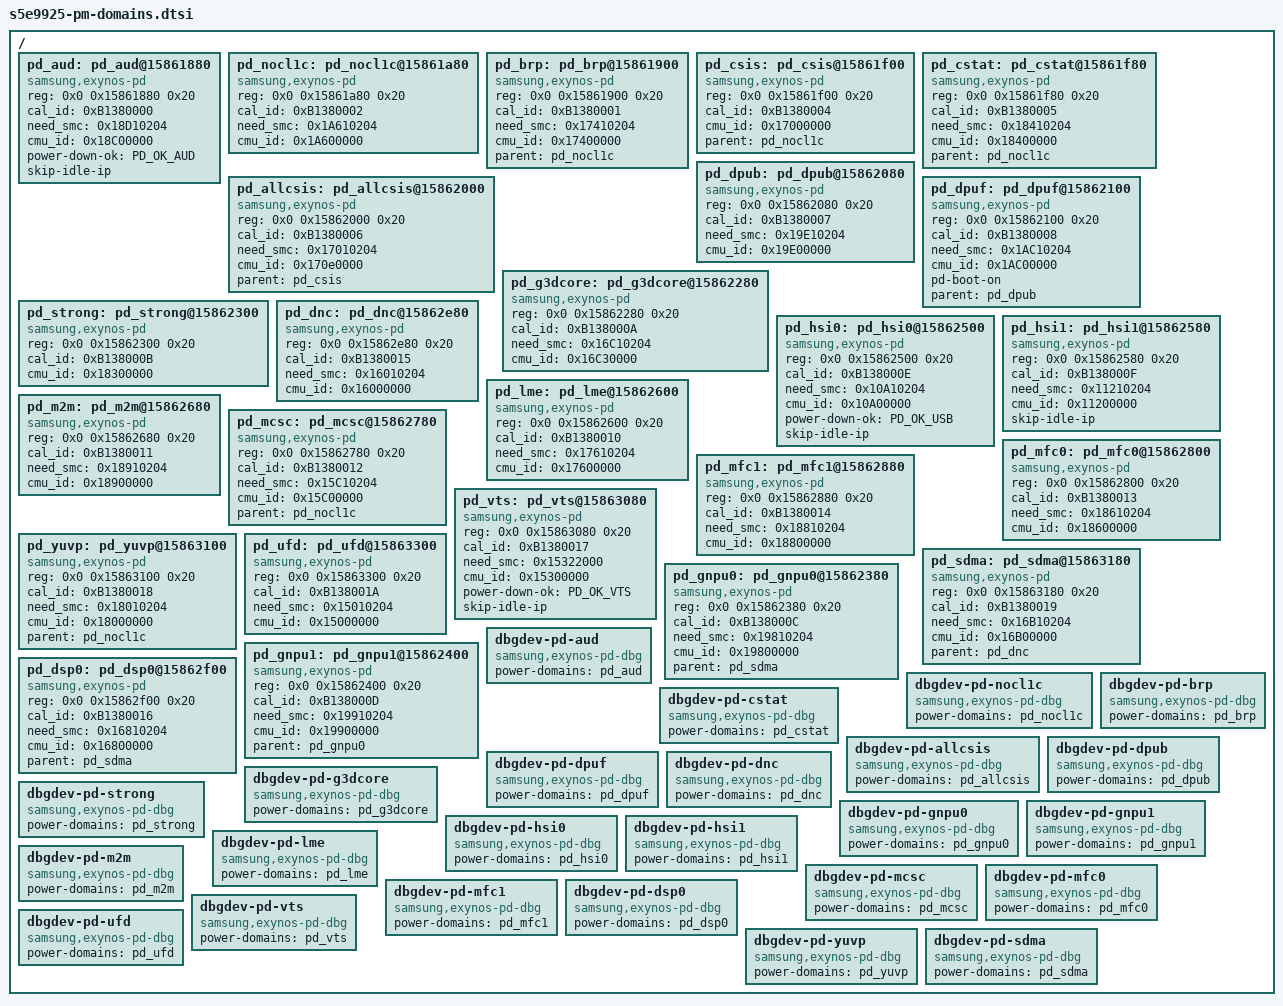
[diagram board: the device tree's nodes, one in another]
/*
 * SAMSUNG S5E9925 SoC PM Domains device tree source
 *
 * Copyright (c) 2019 Samsung Electronics Co., Ltd.
 *		http://www.samsung.com
 *
 * SAMSUNG S5E9925 SoC PM domains device nodes are listed in this file.
 * S5E9925 based board files can include this file and provide
 * values for board specfic bindings.
 *
 * This program is free software; you can redistribute it and/or modify
 * it under the terms of the GNU General Public License version 2 as
 * published by the Free Software Foundation.
 */
#include <dt-bindings/power/exynos-power.h>

/ {
	pd_aud: pd_aud@15861880 {
		compatible = "samsung,exynos-pd";
		reg = <0x0 0x15861880 0x20>;
		cal_id = <0xB1380000>;
		need_smc = <0x18D10204>;
		cmu_id = <0x18C00000>;
		status = "okay";
		power-down-ok = <PD_OK_AUD>;
		#power-domain-cells = <0>;
		skip-idle-ip;
	};
	pd_nocl1c: pd_nocl1c@15861a80 {
		compatible = "samsung,exynos-pd";
		reg = <0x0 0x15861a80 0x20>;
		cal_id = <0xB1380002>;
		need_smc = <0x1A610204>;
		cmu_id = <0x1A600000>;
		status = "okay";
		#power-domain-cells = <0>;
	};
	pd_brp: pd_brp@15861900 {	 
		compatible = "samsung,exynos-pd";
		reg = <0x0 0x15861900 0x20>;
		cal_id = <0xB1380001>;
		need_smc = <0x17410204>;
		cmu_id = <0x17400000>;
		status = "okay";
		parent = <&pd_nocl1c>;
		#power-domain-cells = <0>;
	};
	pd_csis: pd_csis@15861f00 {
		compatible = "samsung,exynos-pd";
		reg = <0x0 0x15861f00 0x20>;
		cal_id = <0xB1380004>;
		cmu_id = <0x17000000>;
		status = "okay";
		parent = <&pd_nocl1c>;
		#power-domain-cells = <0>;
	};
	pd_cstat: pd_cstat@15861f80 {
		compatible = "samsung,exynos-pd";
		reg = <0x0 0x15861f80 0x20>;
		cal_id = <0xB1380005>;
		need_smc = <0x18410204>;
		cmu_id = <0x18400000>;
		status = "okay";
		parent = <&pd_nocl1c>;
		#power-domain-cells = <0>;
	};
	pd_allcsis: pd_allcsis@15862000 {
		compatible = "samsung,exynos-pd";
		reg = <0x0 0x15862000 0x20>;
		cal_id = <0xB1380006>;
		need_smc = <0x17010204>;
		cmu_id = <0x170e0000>;
		status = "okay";
		parent = <&pd_csis>;
		#power-domain-cells = <0>;
	};
	pd_dpub: pd_dpub@15862080 {
		compatible = "samsung,exynos-pd";
		reg = <0x0 0x15862080 0x20>;
		cal_id = <0xB1380007>;
		need_smc = <0x19E10204>;
		cmu_id = <0x19E00000>;
		status = "okay";
		#power-domain-cells = <0>;
	};
	pd_dpuf: pd_dpuf@15862100 {
		compatible = "samsung,exynos-pd";
		reg = <0x0 0x15862100 0x20>;
		cal_id = <0xB1380008>;
		need_smc = <0x1AC10204>;
		cmu_id = <0x1AC00000>;
		status = "okay";
		pd-boot-on;
		parent = <&pd_dpub>;
		#power-domain-cells = <0>;
	};
	pd_g3dcore: pd_g3dcore@15862280 {
		compatible = "samsung,exynos-pd";
		reg = <0x0 0x15862280 0x20>;
		cal_id = <0xB138000A>;
		need_smc = <0x16C10204>;
		cmu_id = <0x16C30000>;
		status = "okay";
		#power-domain-cells = <0>;
	};
	pd_strong: pd_strong@15862300 {
		compatible = "samsung,exynos-pd";
		reg = <0x0 0x15862300 0x20>;
		cal_id = <0xB138000B>;
		cmu_id = <0x18300000>;
		status = "okay";
		#power-domain-cells = <0>;
	};
	pd_dnc: pd_dnc@15862e80 {
		compatible = "samsung,exynos-pd";
		reg = <0x0 0x15862e80 0x20>;
		cal_id = <0xB1380015>;
		need_smc = <0x16010204>;
		cmu_id = <0x16000000>;
		status = "okay";
		#power-domain-cells = <0>;
	};
	pd_hsi0: pd_hsi0@15862500 {
		compatible = "samsung,exynos-pd";
		reg = <0x0 0x15862500 0x20>;
		cal_id = <0xB138000E>;
		need_smc = <0x10A10204>;
		cmu_id = <0x10A00000>;
		status = "okay";
		power-down-ok = <PD_OK_USB>;
		#power-domain-cells = <0>;
		skip-idle-ip;	
	};
	pd_hsi1: pd_hsi1@15862580 {
		compatible = "samsung,exynos-pd";
		reg = <0x0 0x15862580 0x20>;
		cal_id = <0xB138000F>;
		need_smc = <0x11210204>;
		cmu_id = <0x11200000>;
		status = "okay";	
		#power-domain-cells = <0>;
		skip-idle-ip;
	};
	pd_lme: pd_lme@15862600 {
		compatible = "samsung,exynos-pd";
		reg = <0x0 0x15862600 0x20>;
		cal_id = <0xB1380010>;
		need_smc = <0x17610204>;
		cmu_id = <0x17600000>;
		status = "okay";
		#power-domain-cells = <0>;
	};
	pd_m2m: pd_m2m@15862680 {
		compatible = "samsung,exynos-pd";
		reg = <0x0 0x15862680 0x20>;
		cal_id = <0xB1380011>;
		need_smc = <0x18910204>;
		cmu_id = <0x18900000>;
		status = "okay";
		#power-domain-cells = <0>;
	};
	pd_mcsc: pd_mcsc@15862780 {
		compatible = "samsung,exynos-pd";
		reg = <0x0 0x15862780 0x20>;
		cal_id = <0xB1380012>;
		need_smc = <0x15C10204>;
		cmu_id = <0x15C00000>;
		status = "okay";
		parent = <&pd_nocl1c>;
		#power-domain-cells = <0>;
	};
	pd_mfc0: pd_mfc0@15862800 {
		compatible = "samsung,exynos-pd";
		reg = <0x0 0x15862800 0x20>;
		cal_id = <0xB1380013>;
		need_smc = <0x18610204>;
		cmu_id = <0x18600000>;
		status = "okay";
		#power-domain-cells = <0>;
	};
	pd_mfc1: pd_mfc1@15862880 {
		compatible = "samsung,exynos-pd";
		reg = <0x0 0x15862880 0x20>;
		cal_id = <0xB1380014>;
		need_smc = <0x18810204>;
		cmu_id = <0x18800000>;
		status = "okay";
		#power-domain-cells = <0>;
	};
	pd_vts: pd_vts@15863080 {
		compatible = "samsung,exynos-pd";
		reg = <0x0 0x15863080 0x20>;
		cal_id = <0xB1380017>;
		need_smc = <0x15322000>;
		cmu_id = <0x15300000>;
		status = "okay";
		power-down-ok = <PD_OK_VTS>;
		#power-domain-cells = <0>;
		skip-idle-ip;
	};
	pd_yuvp: pd_yuvp@15863100 {
		compatible = "samsung,exynos-pd";
		reg = <0x0 0x15863100 0x20>;
		cal_id = <0xB1380018>;
		need_smc = <0x18010204>;
		cmu_id = <0x18000000>;
		status = "okay";
		parent = <&pd_nocl1c>;
		#power-domain-cells = <0>;
	};
	pd_sdma: pd_sdma@15863180 {
		compatible = "samsung,exynos-pd";
		reg = <0x0 0x15863180 0x20>;
		cal_id = <0xB1380019>;
		need_smc = <0x16B10204>;
		cmu_id = <0x16B00000>;
		status = "okay";
		parent = <&pd_dnc>;
		#power-domain-cells = <0>;
	};
	pd_ufd: pd_ufd@15863300 {
		compatible = "samsung,exynos-pd";
		reg = <0x0 0x15863300 0x20>;
		cal_id = <0xB138001A>;
		need_smc = <0x15010204>;
		cmu_id = <0x15000000>;
		status = "okay";
		#power-domain-cells = <0>;
	};
	pd_gnpu0: pd_gnpu0@15862380 {
		compatible = "samsung,exynos-pd";
		reg = <0x0 0x15862380 0x20>;
		cal_id = <0xB138000C>;
		need_smc = <0x19810204>;
		cmu_id = <0x19800000>;
		status = "okay";
		parent = <&pd_sdma>;
		#power-domain-cells = <0>;
	};
	pd_gnpu1: pd_gnpu1@15862400 {
		compatible = "samsung,exynos-pd";
		reg = <0x0 0x15862400 0x20>;
		cal_id = <0xB138000D>;
		need_smc = <0x19910204>;
		cmu_id = <0x19900000>;
		status = "okay";
		parent = <&pd_gnpu0>;
		#power-domain-cells = <0>;
	};
	pd_dsp0: pd_dsp0@15862f00 {
		compatible = "samsung,exynos-pd";
		reg = <0x0 0x15862f00 0x20>;
		cal_id = <0xB1380016>;
		need_smc = <0x16810204>;
		cmu_id = <0x16800000>;
		status = "okay";
		parent = <&pd_sdma>;
		#power-domain-cells = <0>;
	};
	dbgdev-pd-aud {
		compatible = "samsung,exynos-pd-dbg";
		power-domains = <&pd_aud>;
	};

	dbgdev-pd-nocl1c {
		compatible = "samsung,exynos-pd-dbg";
		power-domains = <&pd_nocl1c>;
	};

	dbgdev-pd-brp {
		compatible = "samsung,exynos-pd-dbg";
		power-domains = <&pd_brp>;
	};

	dbgdev-pd-cstat {
		compatible = "samsung,exynos-pd-dbg";
		power-domains = <&pd_cstat>;
	};

	dbgdev-pd-allcsis {
		compatible = "samsung,exynos-pd-dbg";
		power-domains = <&pd_allcsis>;
	};

	dbgdev-pd-dpub {
		compatible = "samsung,exynos-pd-dbg";
		power-domains = <&pd_dpub>;
	};

	dbgdev-pd-dpuf {
		compatible = "samsung,exynos-pd-dbg";
		power-domains = <&pd_dpuf>;
	};

	dbgdev-pd-g3dcore {
		compatible = "samsung,exynos-pd-dbg";
		power-domains = <&pd_g3dcore>;
	};

	dbgdev-pd-strong {
		compatible = "samsung,exynos-pd-dbg";
		power-domains = <&pd_strong>;
	};

	dbgdev-pd-dnc {
		compatible = "samsung,exynos-pd-dbg";
		power-domains = <&pd_dnc>;
	};

	dbgdev-pd-gnpu0 {
		compatible = "samsung,exynos-pd-dbg";
		power-domains = <&pd_gnpu0>;
	};

	dbgdev-pd-gnpu1 {
		compatible = "samsung,exynos-pd-dbg";
		power-domains = <&pd_gnpu1>;
	};

	dbgdev-pd-hsi0 {
		compatible = "samsung,exynos-pd-dbg";
		power-domains = <&pd_hsi0>;
	};

	dbgdev-pd-hsi1 {
		compatible = "samsung,exynos-pd-dbg";
		power-domains = <&pd_hsi1>;
	};

	dbgdev-pd-lme {
		compatible = "samsung,exynos-pd-dbg";
		power-domains = <&pd_lme>;
	};

	dbgdev-pd-m2m {
		compatible = "samsung,exynos-pd-dbg";
		power-domains = <&pd_m2m>;
	};

	dbgdev-pd-mcsc {
		compatible = "samsung,exynos-pd-dbg";
		power-domains = <&pd_mcsc>;
	};

	dbgdev-pd-mfc0 {
		compatible = "samsung,exynos-pd-dbg";
		power-domains = <&pd_mfc0>;
	};

	dbgdev-pd-mfc1 {
		compatible = "samsung,exynos-pd-dbg";
		power-domains = <&pd_mfc1>;
	};

	dbgdev-pd-dsp0 {
		compatible = "samsung,exynos-pd-dbg";
		power-domains = <&pd_dsp0>;
	};

	dbgdev-pd-vts {
		compatible = "samsung,exynos-pd-dbg";
		power-domains = <&pd_vts>;
	};

	dbgdev-pd-yuvp {
		compatible = "samsung,exynos-pd-dbg";
		power-domains = <&pd_yuvp>;
	};

	dbgdev-pd-sdma {
		compatible = "samsung,exynos-pd-dbg";
		power-domains = <&pd_sdma>;
	};

	dbgdev-pd-ufd {
		compatible = "samsung,exynos-pd-dbg";
		power-domains = <&pd_ufd>;
	};


};
